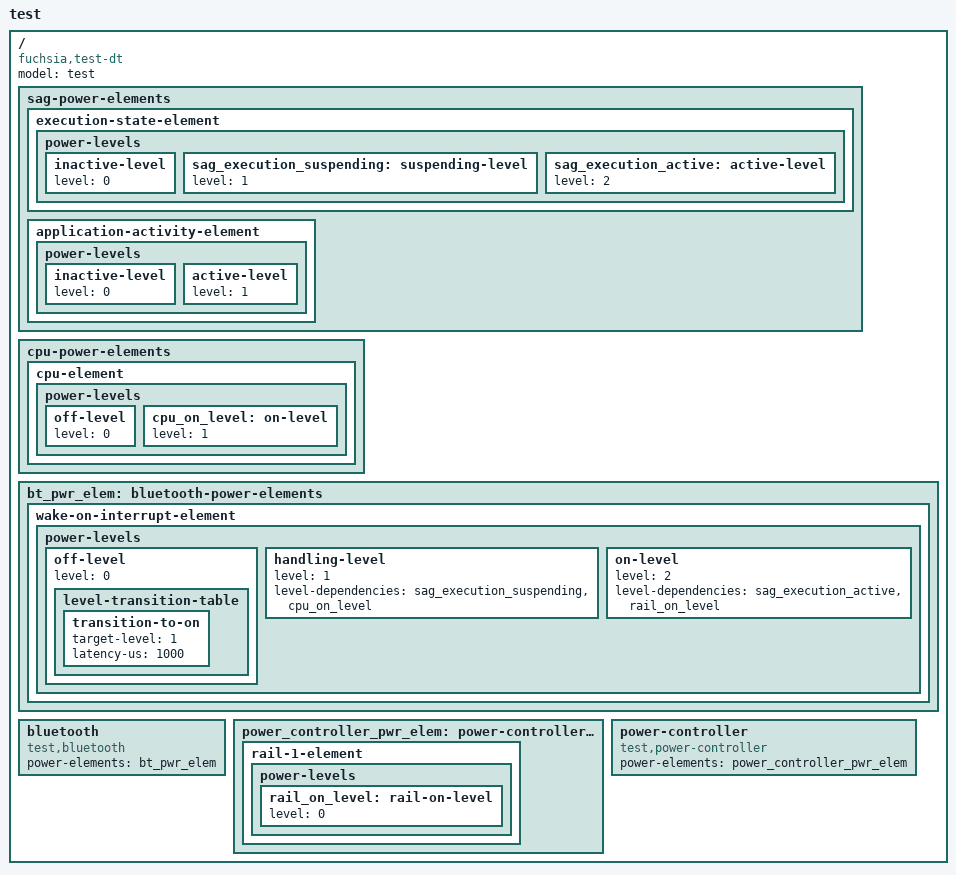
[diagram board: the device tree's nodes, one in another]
// Copyright 2024 The Fuchsia Authors. All rights reserved.
// Use of this source code is governed by a BSD-style license that can be
// found in the LICENSE file.
/dts-v1/;

/ {
	compatible = "fuchsia,test-dt";
	model = "test";
	#address-cells = <2>;
	#size-cells = <2>;

	sag-power-elements {
		execution-state-element {
			power-levels {
				inactive-level {
					level = <0>;
				};

				sag_execution_suspending: suspending-level {
					level = <1>;
				};

				sag_execution_active: active-level {
					level = <2>;
				};
			};
		};

		application-activity-element {
			power-levels {
				inactive-level {
					level = <0>;
				};

				active-level {
					level = <1>;
				};
			};
		};
	};

	cpu-power-elements {
		cpu-element {
			power-levels {
				off-level {
					level = <0>;
				};

				cpu_on_level: on-level {
					level = <1>;
				};
			};
		};
	};

	bt_pwr_elem: bluetooth-power-elements {
		wake-on-interrupt-element {
			power-levels {
				off-level {
					level = <0>;

					level-transition-table {
						transition-to-on {
							target-level = <1>;
							latency-us = <1000>;
						};
					};
				};

				handling-level {
					level = <1>;
					level-dependencies = <&sag_execution_suspending &cpu_on_level>;
				};

				on-level {
					level = <2>;
					level-dependencies = <&sag_execution_active &rail_on_level>;
				};
			};
		};
	};

	bluetooth {
		compatible = "test,bluetooth";
		power-elements = <&bt_pwr_elem>;
	};

	power_controller_pwr_elem: power-controller-power-elements {
		rail-1-element {
			power-levels {
				rail_on_level: rail-on-level {
					level = <0>;
				};
			};
		};
	};

	power-controller {
		compatible = "test,power-controller";
		power-elements = <&power_controller_pwr_elem>;
	};
};
